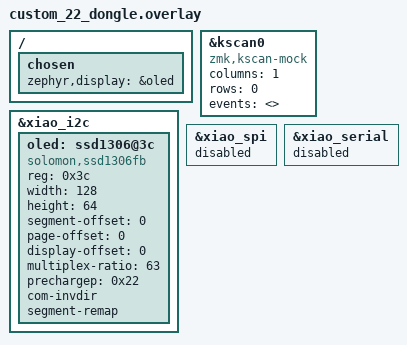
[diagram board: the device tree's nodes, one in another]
#include "custom_22.dtsi"

/ {
    chosen {
        zephyr,display = &oled;
    };
};

&kscan0 {
    compatible = "zmk,kscan-mock";
    /delete-property/ input-gpios;
    columns = <1>;
    rows = <0>;
    events = <>;
};

&xiao_i2c {
    status = "okay";

    oled: ssd1306@3c {
        compatible = "solomon,ssd1306fb";
        reg = <0x3c>;
        width = <128>;
        height = <64>;
        segment-offset = <0>;
        page-offset = <0>;
        display-offset = <0>;
        multiplex-ratio = <63>;
        prechargep = <0x22>;
        com-invdir;
        segment-remap;
    };
};
&xiao_spi { status = "disabled"; };
&xiao_serial { status = "disabled"; };
